# Timer_B7_1 register map
Vendor: Texas Instruments
Peripheral module from a debugger description file (folder msp430).
Registers are 16-bit, access not given, no defined reset value unless marked. A register's access mark holds for its fields unless they carry their own. Offsets are as the file gives them; lines under a group give offsets from that group; [hi:lo] are bit positions; {n}, {i} and the like mark numbered series; 'fields as' and 'values as' point back to an identical list; <NAME> marks a mode.

## Timer_B7
0x11E TBIV — Timer B Interrupt Vector Word
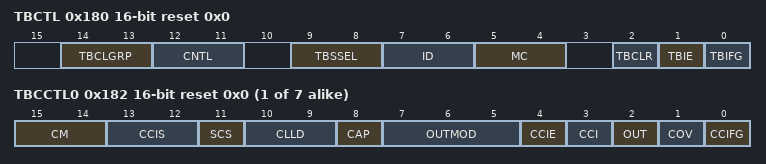
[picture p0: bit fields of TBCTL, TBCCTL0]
0x180 TBCTL rw reset 0x0 — Timer B Control
  [14:13] TBCLGRP — Timer B Compare latch load group 1
    0=Timer B Group: 0 - individually; 1=Timer B Group: 1 - 3 groups (1-2; 2=Timer B Group: 2 - 2 groups (1-3; 3=Timer B Group: 3 - 1 group (all)
  [12:11] CNTL — Counter lenght 1
    0=Counter lenght: 16 bit; 1=Counter lenght: 12 bit; 2=Counter lenght: 10 bit; 3=Counter lenght: 8 bit
  [9:8] TBSSEL — Clock source 1
    0=Clock Source: TBCLK; 1=Clock Source: ACLK; 2=Clock Source: SMCLK; 3=Clock Source: INCLK
  [7:6] ID — Timer B clock input divider 1
    0=Timer A input divider: 0 - /1; 1=Timer A input divider: 1 - /2; 2=Timer A input divider: 2 - /4; 3=Timer A input divider: 3 - /8
  [5:4] MC — Timer B mode control 1
    0=Timer A mode control: 0 - Stop; 1=Timer A mode control: 1 - Up to CCR0; 2=Timer A mode control: 2 - Continous up; 3=Timer A mode control: 3 - Up/Down
  [2] TBCLR — Timer B counter clear
  [1] TBIE — Timer B interrupt enable
  [0] TBIFG — Timer B interrupt flag
{0x182+2i} TBCCTL{i} rw reset 0x0 (i=0..6) — Timer B Capture/Compare Control {i}
  [15:14] CM — Capture mode 1
    0=Capture mode: 0 - disabled; 1=Capture mode: 1 - pos. edge; 2=Capture mode: 1 - neg. edge; 3=Capture mode: 1 - both edges
  [13:12] CCIS — Capture input select 1
    0=Capture input select: 0 - CCIxA; 1=Capture input select: 1 - CCIxB; 2=Capture input select: 2 - GND; 3=Capture input select: 3 - Vcc
  [11] SCS — Capture sychronize
  [10:9] CLLD — Compare latch load source 1
    0=Compare latch load sourec : 0 - immediate; 1=Compare latch load sourec : 1 - TBR counts to 0; 2=Compare latch load sourec : 2 - up/down; 3=Compare latch load sourec : 3 - TBR counts to TBCTL0
  [8] CAP — Capture mode: 1 /Compare mode : 0
  [7:5] OUTMOD — Output mode 2
    0=PWM output mode: 0 - output only; 1=PWM output mode: 1 - set; 2=PWM output mode: 2 - PWM toggle/reset; 3=PWM output mode: 3 - PWM set/reset; 4=PWM output mode: 4 - toggle; 5=PWM output mode: 5 - Reset; 6=PWM output mode: 6 - PWM toggle/set; 7=PWM output mode: 7 - PWM reset/set
  [4] CCIE — Capture/compare interrupt enable
  [3] CCI — Capture input signal (read)
  [2] OUT — PWM Output signal if output mode 0
  [1] COV — Capture/compare overflow flag
  [0] CCIFG — Capture/compare interrupt flag
0x190 TBR — Timer B Counter Register
{0x192+2i} TBCCR{i} (i=0..6) — Timer B Capture/Compare {i}
